# PIC32CX5109BZ31048 register map
Vendor: Microchip Technology; Series: PIC32CXBZ31; File version: 0
CPU: CM4 r0p1, little endian, MPU, FPU, 3 interrupt priority bits, 43 interrupts
Registers are 32-bit, read-write, reset 0x0 unless marked. A register's access mark holds for its fields unless they carry their own. Offsets are from the block's base; [hi:lo] are bit positions; lines under a group give offsets from that group; {n}, {i} and the like mark numbered series.

## FPU — Floating Point Unit
Base 0xE000EF30
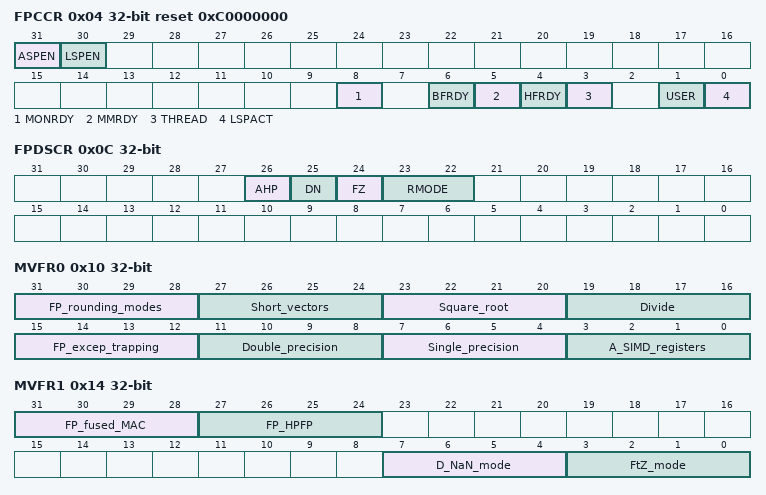
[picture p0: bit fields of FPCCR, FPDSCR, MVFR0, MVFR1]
0x04 FPCCR reset 0xC0000000 — Floating-Point Context Control Register
  [31] ASPEN, [30] LSPEN, [8] MONRDY, [6] BFRDY, [5] MMRDY, [4] HFRDY, [3] THREAD, [1] USER, [0] LSPACT
0x08 FPCAR — Floating-Point Context Address Register
  [31:3] ADDRESS — Address for FP registers in exception stack frame
0x0C FPDSCR — Floating-Point Default Status Control Register
  [26] AHP — Default value for FPSCR.AHP
  [25] DN — Default value for FPSCR.DN
  [24] FZ — Default value for FPSCR.FZ
  [23:22] RMODE — Default value for FPSCR.RMODE
    0=RN (Round to Nearest); 1=RP (Round towards Positive Infinity); 2=RM (Round towards Negative Infinity); 3=RZ (Round towards Zero)
0x10 MVFR0 ro — Media and FP Feature Register 0
  [31:28] FP_rounding_modes, [27:24] Short_vectors, [23:20] Square_root, [19:16] Divide, [15:12] FP_excep_trapping, [11:8] Double_precision, [7:4] Single_precision, [3:0] A_SIMD_registers
0x14 MVFR1 ro — Media and FP Feature Register 1
  [31:28] FP_fused_MAC, [27:24] FP_HPFP, [7:4] D_NaN_mode, [3:0] FtZ_mode

## FREQM — Frequency Meter
Base 0x40000400
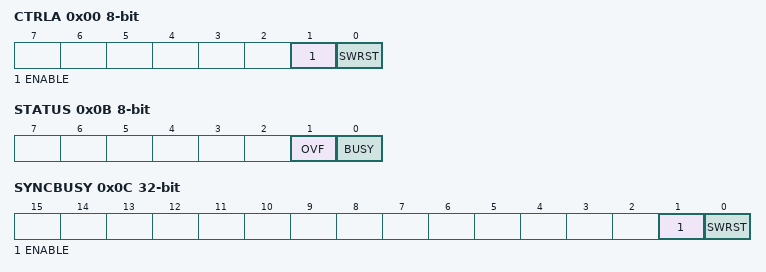
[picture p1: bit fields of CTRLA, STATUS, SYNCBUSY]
0x00 CTRLA 8-bit — Control A Register
  [1] ENABLE
  [0] SWRST — Software Reset
0x01 CTRLB 8-bit wo — Control B Register
  [0] START — Start Measurement
0x02 CFGA 16-bit — Config A register
  [7:0] REFNUM — Number of Reference Clock Cycles
0x08 INTENCLR 8-bit — Interrupt Enable Clear Register
  [0] DONE — Measurement Done Interrupt Enable
0x09 INTENSET 8-bit — Interrupt Enable Set Register
  [0] DONE — Measurement Done Interrupt Enable
0x0A INTFLAG 8-bit — Interrupt Flag Register
  [0] DONE — Measurement Done
0x0B STATUS 8-bit
  [1] OVF — Sticky Count Value Overflow
  [0] BUSY — FREQM Status
0x0C SYNCBUSY ro — Synchronization Busy Register
  [1] ENABLE
  [0] SWRST — Software Reset
0x10 VALUE ro — Count Value Register
  [23:0] VALUE — Measurement Value

## GPIOA — GPIO
Base 0x44002A00; register names take the prefix GPIO_
Same registers: GPIOB 0x44002B00
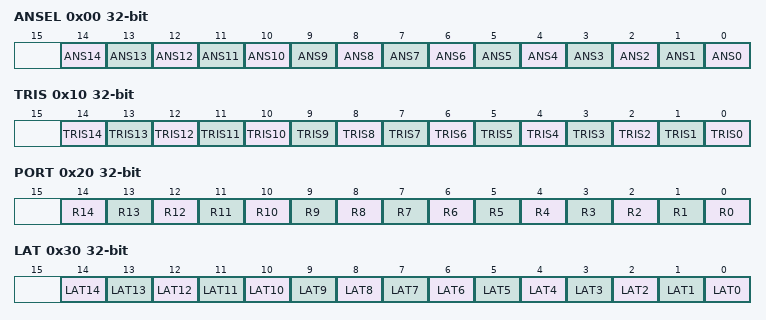
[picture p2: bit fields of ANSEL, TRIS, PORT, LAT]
0x00 ANSEL
  [n] ANS{n} (n=0..14)
0x04 ANSELCLR
0x08 ANSELSET
0x0C ANSELINV
0x10 TRIS
  [n] TRIS{n} (n=0..14)
0x14 TRISCLR
0x18 TRISSET
0x1C TRISINV
0x20 PORT
  [n] R{n} (n=0..14)
0x24 PORTCLR
0x28 PORTSET
0x2C PORTINV
0x30 LAT
  [n] LAT{n} (n=0..14)
0x34 LATCLR
0x38 LATSET
0x3C LATINV
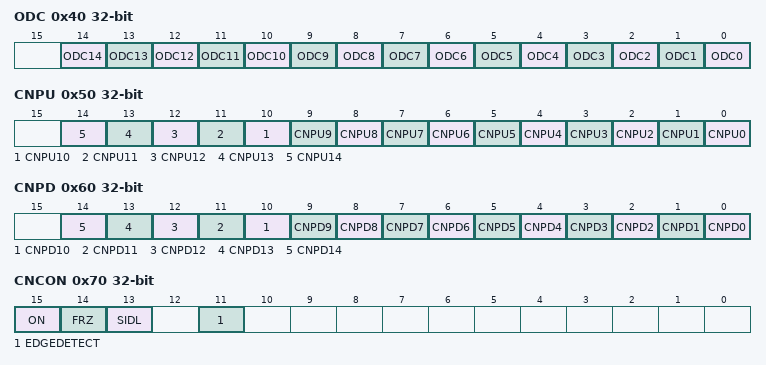
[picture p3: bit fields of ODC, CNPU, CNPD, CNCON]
0x40 ODC
  [n] ODC{n} (n=0..14)
0x44 ODCCLR
0x48 ODCSET
0x4C ODCINV
0x50 CNPU
  [n] CNPU{n} (n=0..14)
0x54 CNPUCLR
0x58 CNPUSET
0x5C CNPUINV
0x60 CNPD
  [n] CNPD{n} (n=0..14)
0x64 CNPDCLR
0x68 CNPDSET
0x6C CNPDINV
0x70 CNCON
  [15] ON, [14] FRZ, [13] SIDL, [11] EDGEDETECT
0x74 CNCONCLR
0x78 CNCONSET
0x7C CNCONINV
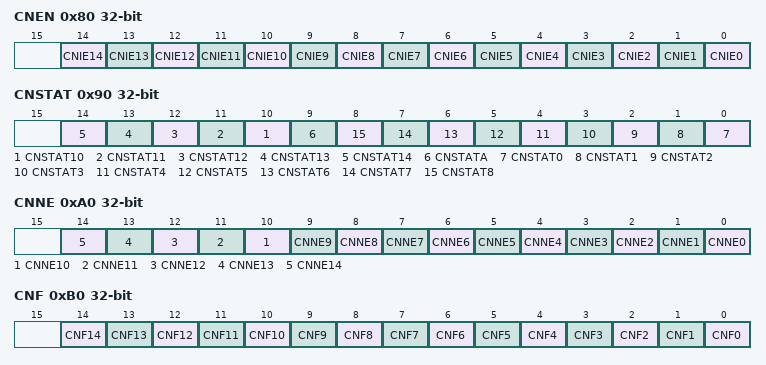
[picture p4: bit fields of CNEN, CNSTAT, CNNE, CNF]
0x80 CNEN
  [n] CNIE{n} (n=0..14)
0x84 CNENCLR
0x88 CNENSET
0x8C CNENINV
0x90 CNSTAT
  [n] CNSTAT{n} (n=10..14), [9] CNSTATA, [n] CNSTAT{n} (n=0..8)
0x94 CNSTATCLR
0x98 CNSTATSET
0x9C CNSTATINV
0xA0 CNNE
  [n] CNNE{n} (n=0..14)
0xA4 CNNECLR
0xA8 CNNESET
0xAC CNNEINV
0xB0 CNF
  [n] CNF{n} (n=0..14)
0xB4 CNFCLR
0xB8 CNFSET
0xBC CNFINV
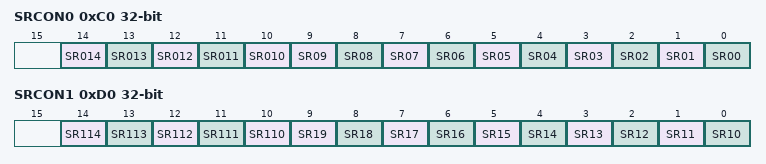
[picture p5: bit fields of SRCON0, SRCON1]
0xC0 SRCON0
  [n] SR{n:03} (n=10..14), [n] SR{n:02} (n=0..9)
0xC4 SRCON0CLR
0xC8 SRCON0SET
0xCC SRCON0INV
0xD0 SRCON1
  [n-100] SR{n} (n=110..114), [n-10] SR{n} (n=10..19)
0xD4 SRCON1CLR
0xD8 SRCON1SET
0xDC SRCON1INV

## HMATRIX2TOP — HSB Matrix
Base 0x42002400
{0x80+8i} PRS[{i}] (i=0..15) group
  0x00 PRAS — Priority A for Slave
  0x04 PRBS — Priority B for Slave

## ITM — Instrumentation Trace Macrocell
Base 0xE0000000
{0x0+4i} PORT_BYTE_MODE[{i}] (i=0..31) wo — ITM Stimulus Port Registers
  [7:0] PORT
{0x0+4i} PORT_HWORD_MODE[{i}] (i=0..31) wo (alternate view of PORT_BYTE_MODE[{i}]) — ITM Stimulus Port Registers
  [15:0] PORT
{0x0+4i} PORT_WORD_MODE[{i}] (i=0..31) wo (alternate view of PORT_BYTE_MODE[{i}]) — ITM Stimulus Port Registers
  [31:0] PORT
0xE00 TER — ITM Trace Enable Register
0xE40 TPR — ITM Trace Privilege Register
  [3:0] PRIVMASK
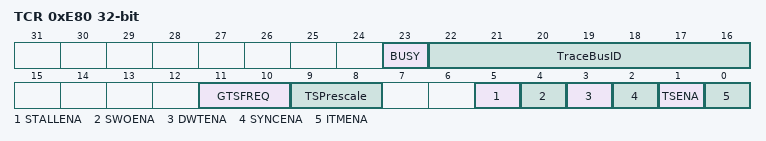
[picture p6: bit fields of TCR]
0xE80 TCR — ITM Trace Control Register
  [23] BUSY, [22:16] TraceBusID, [11:10] GTSFREQ, [9:8] TSPrescale, [5] STALLENA, [4] SWOENA, [3] DWTENA, [2] SYNCENA, [1] TSENA, [0] ITMENA
0xEF8 IWR wo — ITM Integration Write Register
  [0] ATVALIDM
0xEFC IRR ro — ITM Integration Read Register
  [0] ATREADYM
0xFD0 PID4 ro reset 0x4 — ITM Peripheral Identification Register #4
{0xFC0+4i} PID{i} ro (i=5..7) — ITM Peripheral Identification Register #{i}
0xFE0 PID0 ro reset 0x1 — ITM Peripheral Identification Register #0
0xFE4 PID1 ro reset 0xB0 — ITM Peripheral Identification Register #1
0xFE8 PID2 ro reset 0x3B — ITM Peripheral Identification Register #2
0xFEC PID3 ro — ITM Peripheral Identification Register #3
0xFF0 CID0 ro reset 0xD — ITM Component Identification Register #0
0xFF4 CID1 ro reset 0xE0 — ITM Component Identification Register #1
0xFF8 CID2 ro reset 0x5 — ITM Component Identification Register #2
0xFFC CID3 ro reset 0xB1 — ITM Component Identification Register #3

## Notices in the file
Copyright (c) 2023 Microchip Technology Inc.
SPDX-License-Identifier: Apache-2.0
Licensed under the Apache License, Version 2.0 (the "License");
you may not use this file except in compliance with the License.
You may obtain a copy of the License at
http://www.apache.org/licenses/LICENSE-2.0
Unless required by applicable law or agreed to in writing, software
distributed under the License is distributed on an "AS IS" BASIS,
WITHOUT WARRANTIES OR CONDITIONS OF ANY KIND, either express or implied.
See the License for the specific language governing permissions and
limitations under the License.
